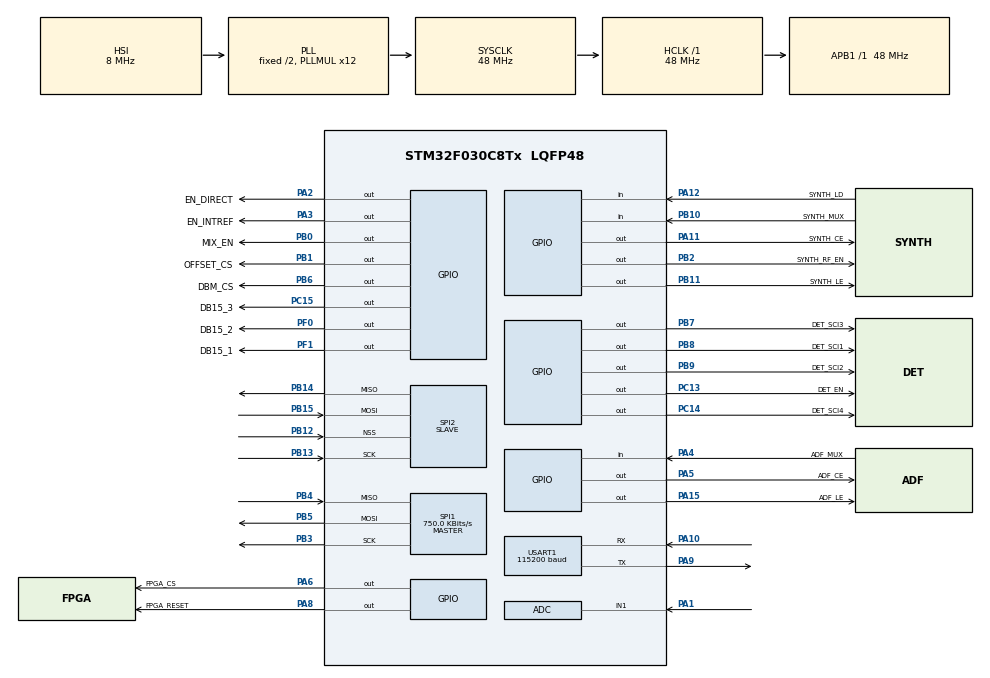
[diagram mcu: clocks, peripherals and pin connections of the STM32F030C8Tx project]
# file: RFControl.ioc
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ADC.Channel-0\#ChannelRegularConversion=ADC_CHANNEL_1
ADC.Channel-IN1=ADC_CHANNEL_1
ADC.ClockPrescaler=ADC_CLOCK_ASYNC_DIV1
ADC.ContinuousConvMode=ENABLE
ADC.DMAContinuousRequests=ENABLE
ADC.DataAlign=ADC_DATAALIGN_RIGHT
ADC.DiscontinuousConvMode=DISABLE
ADC.EOCSelection=ADC_EOC_SINGLE_CONV
ADC.EnableAnalogWatchDog=false
ADC.ExternalTrigConv=ADC_SOFTWARE_START
ADC.ExternalTrigConvEdge=ADC_EXTERNALTRIGCONVEDGE_NONE
ADC.LowPowerAutoPowerOff=DISABLE
ADC.LowPowerAutoWait=DISABLE
ADC.NbrOfConversion=1
ADC.NbrOfConversionFlag=1
ADC.Overrun=ADC_OVR_DATA_PRESERVED
ADC.Rank-0\#ChannelRegularConversion=1
ADC.Resolution=ADC_RESOLUTION_12B
ADC.SamplingTime=ADC_SAMPLETIME_239CYCLES_5
ADC.ScanConvMode=ADC_SCAN_DIRECTION_FORWARD
ADC.master=1
Dma.ADC.0.Direction=DMA_PERIPH_TO_MEMORY
Dma.ADC.0.Instance=DMA1_Channel1
Dma.ADC.0.MemDataAlignment=DMA_MDATAALIGN_HALFWORD
Dma.ADC.0.MemInc=DMA_MINC_ENABLE
Dma.ADC.0.Mode=DMA_CIRCULAR
Dma.ADC.0.PeriphDataAlignment=DMA_PDATAALIGN_HALFWORD
Dma.ADC.0.PeriphInc=DMA_PINC_DISABLE
Dma.ADC.0.Priority=DMA_PRIORITY_LOW
Dma.Request0=ADC
Dma.Request1=SPI2_RX
Dma.Request2=SPI2_TX
Dma.SPI2_RX.1.Direction=DMA_PERIPH_TO_MEMORY
Dma.SPI2_RX.1.Instance=DMA1_Channel4
Dma.SPI2_RX.1.MemDataAlignment=DMA_MDATAALIGN_BYTE
Dma.SPI2_RX.1.MemInc=DMA_MINC_ENABLE
Dma.SPI2_RX.1.Mode=DMA_NORMAL
Dma.SPI2_RX.1.PeriphDataAlignment=DMA_PDATAALIGN_BYTE
Dma.SPI2_RX.1.PeriphInc=DMA_PINC_DISABLE
Dma.SPI2_RX.1.Priority=DMA_PRIORITY_LOW
Dma.SPI2_TX.2.Direction=DMA_MEMORY_TO_PERIPH
Dma.SPI2_TX.2.Instance=DMA1_Channel5
Dma.SPI2_TX.2.MemDataAlignment=DMA_MDATAALIGN_BYTE
Dma.SPI2_TX.2.MemInc=DMA_MINC_ENABLE
Dma.SPI2_TX.2.Mode=DMA_NORMAL
Dma.SPI2_TX.2.PeriphDataAlignment=DMA_PDATAALIGN_BYTE
Dma.SPI2_TX.2.PeriphInc=DMA_PINC_DISABLE
Dma.SPI2_TX.2.Priority=DMA_PRIORITY_LOW
Mcu.Family=STM32F0
Mcu.Name=STM32F030C8Tx
Mcu.Package=LQFP48
NVIC.DMA1_Channel1_IRQn=true\:0\:0\:false\:false\:true\:false\:true
NVIC.DMA1_Channel4_5_IRQn=true\:0\:0\:false\:false\:true\:false\:true
PA1.Mode=IN1
PA1.Signal=ADC_IN1
PA10.Mode=Asynchronous
PA10.Signal=USART1_RX
PA11.GPIO_Label=SYNTH_CE
PA11.Signal=GPIO_Output
PA12.GPIO_Label=SYNTH_LD
PA12.GPIO_PuPd=GPIO_PULLUP
PA12.Signal=GPIO_Input
PA13.Mode=Serial_Wire
PA13.Signal=SYS_SWDIO
PA14.Mode=Serial_Wire
PA14.Signal=SYS_SWCLK
PA15.GPIO_Label=ADF_LE
PA15.Signal=GPIO_Output
PA2.GPIO_Label=EN_DIRECT
PA2.PinState=GPIO_PIN_SET
PA2.Signal=GPIO_Output
PA3.GPIO_Label=EN_INTREF
PA3.PinState=GPIO_PIN_SET
PA3.Signal=GPIO_Output
PA4.GPIO_Label=ADF_MUX
PA4.GPIO_PuPd=GPIO_PULLUP
PA4.Signal=GPIO_Input
PA5.GPIO_Label=ADF_CE
PA5.Signal=GPIO_Output
PA6.GPIO_Label=FPGA_CS
PA6.PinState=GPIO_PIN_SET
PA6.Signal=GPIO_Output
PA8.GPIO_Label=FPGA_RESET
PA8.Signal=GPIO_Output
PA9.Mode=Asynchronous
PA9.Signal=USART1_TX
PB0.GPIO_Label=MIX_EN
PB0.Signal=GPIO_Output
PB1.GPIO_Label=OFFSET_CS
PB1.PinState=GPIO_PIN_SET
PB1.Signal=GPIO_Output
PB10.GPIO_Label=SYNTH_MUX
PB10.Signal=GPIO_Input
PB11.GPIO_Label=SYNTH_LE
PB11.Signal=GPIO_Output
PB12.Mode=NSS_Signal_Hard_Input
PB12.Signal=SPI2_NSS
PB13.Mode=Full_Duplex_Slave
PB13.Signal=SPI2_SCK
PB14.Mode=Full_Duplex_Slave
PB14.Signal=SPI2_MISO
PB15.Mode=Full_Duplex_Slave
PB15.Signal=SPI2_MOSI
PB2.GPIO_Label=SYNTH_RF_EN
PB2.Signal=GPIO_Output
PB3.Mode=Full_Duplex_Master
PB3.Signal=SPI1_SCK
PB4.Mode=Full_Duplex_Master
PB4.Signal=SPI1_MISO
PB5.Mode=Full_Duplex_Master
PB5.Signal=SPI1_MOSI
PB6.GPIO_Label=DBM_CS
PB6.PinState=GPIO_PIN_SET
PB6.Signal=GPIO_Output
PB7.GPIO_Label=DET_SCI3
PB7.Signal=GPIO_Output
PB8.GPIO_Label=DET_SCI1
PB8.Signal=GPIO_Output
PB9.GPIO_Label=DET_SCI2
PB9.Signal=GPIO_Output
PC13.GPIO_Label=DET_EN
PC13.PinState=GPIO_PIN_SET
PC13.Signal=GPIO_Output
PC14-OSC32_IN.GPIO_Label=DET_SCI4
PC14-OSC32_IN.Signal=GPIO_Output
PC15-OSC32_OUT.GPIO_Label=DB15_3
PC15-OSC32_OUT.PinState=GPIO_PIN_SET
PC15-OSC32_OUT.Signal=GPIO_Output
PF0-OSC_IN.GPIO_Label=DB15_2
PF0-OSC_IN.PinState=GPIO_PIN_SET
PF0-OSC_IN.Signal=GPIO_Output
PF1-OSC_OUT.GPIO_Label=DB15_1
PF1-OSC_OUT.PinState=GPIO_PIN_SET
PF1-OSC_OUT.Signal=GPIO_Output
ProjectManager.HeapSize=0x200
ProjectManager.StackSize=0x400
ProjectManager.TargetToolchain=SW4STM32
RCC.AHBFreq_Value=48000000
RCC.APB1Freq_Value=48000000
RCC.APB1TimFreq_Value=48000000
RCC.FLatency=FLASH_LATENCY_1
RCC.HCLKFreq_Value=48000000
RCC.PLLMUL=RCC_PLL_MUL12
RCC.RCC_MCOSource=RCC_MCO1SOURCE_HSI
RCC.SYSCLKFreq_VALUE=48000000
RCC.SYSCLKSource=RCC_SYSCLKSOURCE_PLLCLK
SPI1.BaudRatePrescaler=SPI_BAUDRATEPRESCALER_64
SPI1.CLKPhase=SPI_PHASE_1EDGE
SPI1.CLKPolarity=SPI_POLARITY_LOW
SPI1.CRCCalculation=SPI_CRCCALCULATION_DISABLE
SPI1.CalculateBaudRate=750.0 KBits/s
SPI1.DataSize=SPI_DATASIZE_8BIT
SPI1.Direction=SPI_DIRECTION_2LINES
SPI1.FirstBit=SPI_FIRSTBIT_MSB
SPI1.Mode=SPI_MODE_MASTER
SPI1.NSS=SPI_NSS_SOFT
SPI1.NSSPMode=SPI_NSS_PULSE_ENABLE
SPI1.TIMode=SPI_TIMODE_DISABLE
SPI1.VirtualType=VM_MASTER
SPI2.CLKPhase=SPI_PHASE_1EDGE
SPI2.CLKPolarity=SPI_POLARITY_LOW
SPI2.CRCCalculation=SPI_CRCCALCULATION_DISABLE
SPI2.DataSize=SPI_DATASIZE_8BIT
SPI2.Direction=SPI_DIRECTION_2LINES
SPI2.FirstBit=SPI_FIRSTBIT_MSB
SPI2.Mode=SPI_MODE_SLAVE
SPI2.NSS=SPI_NSS_HARD_INPUT
SPI2.TIMode=SPI_TIMODE_DISABLE
SPI2.VirtualNSS=VM_NSSHARD
SPI2.VirtualType=VM_SLAVE
TIM1.AutoReloadPreload=TIM_AUTORELOAD_PRELOAD_DISABLE
TIM1.ClockDivision=TIM_CLOCKDIVISION_DIV1
TIM1.CounterMode=TIM_COUNTERMODE_UP
TIM1.Period=65535
TIM1.Prescaler=47
TIM1.RepetitionCounter=0
TIM1.TIM_MasterOutputTrigger=TIM_TRGO_RESET
TIM1.TIM_MasterSlaveMode=TIM_MASTERSLAVEMODE_DISABLE
USART1.AutoBaudRateEnableParam=UART_ADVFEATURE_AUTOBAUDRATE_DISABLE
USART1.BaudRate=115200
USART1.DMADisableonRxErrorParam=ADVFEATURE_DMA_ENABLEONRXERROR
USART1.DataInvertParam=ADVFEATURE_DATAINV_DISABLE
USART1.MSBFirstParam=ADVFEATURE_MSBFIRST_DISABLE
USART1.Mode=MODE_TX_RX
USART1.OneBitSampling=UART_ONE_BIT_SAMPLE_DISABLE
USART1.OverSampling=UART_OVERSAMPLING_16
USART1.OverrunDisableParam=ADVFEATURE_OVERRUN_ENABLE
USART1.Parity=PARITY_NONE
USART1.RxPinLevelInvertParam=ADVFEATURE_RXINV_DISABLE
USART1.StopBits=STOPBITS_1
USART1.SwapParam=ADVFEATURE_SWAP_DISABLE
USART1.TxPinLevelInvertParam=ADVFEATURE_TXINV_DISABLE
USART1.VirtualMode-Asynchronous=VM_ASYNC
USART1.WordLength=WORDLENGTH_8B
VP_TIM1_VS_ClockSourceINT.Mode=Internal
board=RFControl

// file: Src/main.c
/* USER CODE BEGIN Header */
/**
  ******************************************************************************
  * @file           : main.c
  * @brief          : Main program body
  ******************************************************************************
  * @attention
  *
  * <h2><center>&copy; Copyright (c) 2019 STMicroelectronics.
  * All rights reserved.</center></h2>
  *
  * This software component is licensed by ST under BSD 3-Clause license,
  * the "License"; You may not use this file except in compliance with the
  * License. You may obtain a copy of the License at:
  *                        opensource.org/licenses/BSD-3-Clause
  *
  ******************************************************************************
  */
/* USER CODE END Header */

#include "main.h"

/* USER CODE BEGIN Includes */
#include "../Application/app.h"
/* USER CODE END Includes */

ADC_HandleTypeDef hadc;
DMA_HandleTypeDef hdma_adc;

SPI_HandleTypeDef hspi1;
SPI_HandleTypeDef hspi2;
DMA_HandleTypeDef hdma_spi2_rx;
DMA_HandleTypeDef hdma_spi2_tx;

TIM_HandleTypeDef htim1;

UART_HandleTypeDef huart1;

void SystemClock_Config(void);
static void MX_GPIO_Init(void);
static void MX_DMA_Init(void);
static void MX_USART1_UART_Init(void);
static void MX_SPI1_Init(void);
static void MX_ADC_Init(void);
static void MX_SPI2_Init(void);
static void MX_TIM1_Init(void);

int main(void)
{

  /* MCU Configuration--------------------------------------------------------*/

  /* Reset of all peripherals, Initializes the Flash interface and the Systick. */
  HAL_Init();

  /* Configure the system clock */
  SystemClock_Config();

  /* Initialize all configured peripherals */
  MX_GPIO_Init();
  MX_DMA_Init();
  MX_USART1_UART_Init();
  MX_SPI1_Init();
  MX_ADC_Init();
  MX_SPI2_Init();
  MX_TIM1_Init();

  /* Infinite loop */
  /* USER CODE BEGIN WHILE */
  app();
  while (1)
  {
    /* USER CODE END WHILE */

  }
}

void SystemClock_Config(void)
{
  RCC_OscInitTypeDef RCC_OscInitStruct = {0};
  RCC_ClkInitTypeDef RCC_ClkInitStruct = {0};
  RCC_PeriphCLKInitTypeDef PeriphClkInit = {0};

  /** Initializes the CPU, AHB and APB busses clocks
  */
  RCC_OscInitStruct.OscillatorType = RCC_OSCILLATORTYPE_HSI|RCC_OSCILLATORTYPE_HSI14;
  RCC_OscInitStruct.HSIState = RCC_HSI_ON;
  RCC_OscInitStruct.HSI14State = RCC_HSI14_ON;
  RCC_OscInitStruct.HSICalibrationValue = RCC_HSICALIBRATION_DEFAULT;
  RCC_OscInitStruct.HSI14CalibrationValue = 16;
  RCC_OscInitStruct.PLL.PLLState = RCC_PLL_ON;
  RCC_OscInitStruct.PLL.PLLSource = RCC_PLLSOURCE_HSI;
  RCC_OscInitStruct.PLL.PLLMUL = RCC_PLL_MUL12;
  RCC_OscInitStruct.PLL.PREDIV = RCC_PREDIV_DIV1;
  if (HAL_RCC_OscConfig(&RCC_OscInitStruct) != HAL_OK)
  {
    Error_Handler();
  }
  /** Initializes the CPU, AHB and APB busses clocks
  */
  RCC_ClkInitStruct.ClockType = RCC_CLOCKTYPE_HCLK|RCC_CLOCKTYPE_SYSCLK
                              |RCC_CLOCKTYPE_PCLK1;
  RCC_ClkInitStruct.SYSCLKSource = RCC_SYSCLKSOURCE_PLLCLK;
  RCC_ClkInitStruct.AHBCLKDivider = RCC_SYSCLK_DIV1;
  RCC_ClkInitStruct.APB1CLKDivider = RCC_HCLK_DIV1;

  if (HAL_RCC_ClockConfig(&RCC_ClkInitStruct, FLASH_LATENCY_1) != HAL_OK)
  {
    Error_Handler();
  }
  PeriphClkInit.PeriphClockSelection = RCC_PERIPHCLK_USART1;
  PeriphClkInit.Usart1ClockSelection = RCC_USART1CLKSOURCE_PCLK1;
  if (HAL_RCCEx_PeriphCLKConfig(&PeriphClkInit) != HAL_OK)
  {
    Error_Handler();
  }
}

static void MX_ADC_Init(void)
{

  ADC_ChannelConfTypeDef sConfig = {0};

  /** Configure the global features of the ADC (Clock, Resolution, Data Alignment and number of conversion)
  */
  hadc.Instance = ADC1;
  hadc.Init.ClockPrescaler = ADC_CLOCK_ASYNC_DIV1;
  hadc.Init.Resolution = ADC_RESOLUTION_12B;
  hadc.Init.DataAlign = ADC_DATAALIGN_RIGHT;
  hadc.Init.ScanConvMode = ADC_SCAN_DIRECTION_FORWARD;
  hadc.Init.EOCSelection = ADC_EOC_SINGLE_CONV;
  hadc.Init.LowPowerAutoWait = DISABLE;
  hadc.Init.LowPowerAutoPowerOff = DISABLE;
  hadc.Init.ContinuousConvMode = ENABLE;
  hadc.Init.DiscontinuousConvMode = DISABLE;
  hadc.Init.ExternalTrigConv = ADC_SOFTWARE_START;
  hadc.Init.ExternalTrigConvEdge = ADC_EXTERNALTRIGCONVEDGE_NONE;
  hadc.Init.DMAContinuousRequests = ENABLE;
  hadc.Init.Overrun = ADC_OVR_DATA_PRESERVED;
  if (HAL_ADC_Init(&hadc) != HAL_OK)
  {
    Error_Handler();
  }
  /** Configure for the selected ADC regular channel to be converted.
  */
  sConfig.Channel = ADC_CHANNEL_1;
  sConfig.Rank = ADC_RANK_CHANNEL_NUMBER;
  sConfig.SamplingTime = ADC_SAMPLETIME_239CYCLES_5;
  if (HAL_ADC_ConfigChannel(&hadc, &sConfig) != HAL_OK)
  {
    Error_Handler();
  }

}

static void MX_SPI1_Init(void)
{

  /* SPI1 parameter configuration*/
  hspi1.Instance = SPI1;
  hspi1.Init.Mode = SPI_MODE_MASTER;
  hspi1.Init.Direction = SPI_DIRECTION_2LINES;
  hspi1.Init.DataSize = SPI_DATASIZE_8BIT;
  hspi1.Init.CLKPolarity = SPI_POLARITY_LOW;
  hspi1.Init.CLKPhase = SPI_PHASE_1EDGE;
  hspi1.Init.NSS = SPI_NSS_SOFT;
  hspi1.Init.BaudRatePrescaler = SPI_BAUDRATEPRESCALER_64;
  hspi1.Init.FirstBit = SPI_FIRSTBIT_MSB;
  hspi1.Init.TIMode = SPI_TIMODE_DISABLE;
  hspi1.Init.CRCCalculation = SPI_CRCCALCULATION_DISABLE;
  hspi1.Init.CRCPolynomial = 7;
  hspi1.Init.CRCLength = SPI_CRC_LENGTH_DATASIZE;
  hspi1.Init.NSSPMode = SPI_NSS_PULSE_ENABLE;
  if (HAL_SPI_Init(&hspi1) != HAL_OK)
  {
    Error_Handler();
  }

}

static void MX_SPI2_Init(void)
{

  /* SPI2 parameter configuration*/
  hspi2.Instance = SPI2;
  hspi2.Init.Mode = SPI_MODE_SLAVE;
  hspi2.Init.Direction = SPI_DIRECTION_2LINES;
  hspi2.Init.DataSize = SPI_DATASIZE_8BIT;
  hspi2.Init.CLKPolarity = SPI_POLARITY_LOW;
  hspi2.Init.CLKPhase = SPI_PHASE_1EDGE;
  hspi2.Init.NSS = SPI_NSS_HARD_INPUT;
  hspi2.Init.FirstBit = SPI_FIRSTBIT_MSB;
  hspi2.Init.TIMode = SPI_TIMODE_DISABLE;
  hspi2.Init.CRCCalculation = SPI_CRCCALCULATION_DISABLE;
  hspi2.Init.CRCPolynomial = 7;
  hspi2.Init.CRCLength = SPI_CRC_LENGTH_DATASIZE;
  hspi2.Init.NSSPMode = SPI_NSS_PULSE_DISABLE;
  if (HAL_SPI_Init(&hspi2) != HAL_OK)
  {
    Error_Handler();
  }

}

static void MX_TIM1_Init(void)
{

  TIM_ClockConfigTypeDef sClockSourceConfig = {0};
  TIM_MasterConfigTypeDef sMasterConfig = {0};

  htim1.Instance = TIM1;
  htim1.Init.Prescaler = 47;
  htim1.Init.CounterMode = TIM_COUNTERMODE_UP;
  htim1.Init.Period = 65535;
  htim1.Init.ClockDivision = TIM_CLOCKDIVISION_DIV1;
  htim1.Init.RepetitionCounter = 0;
  htim1.Init.AutoReloadPreload = TIM_AUTORELOAD_PRELOAD_DISABLE;
  if (HAL_TIM_Base_Init(&htim1) != HAL_OK)
  {
    Error_Handler();
  }
  sClockSourceConfig.ClockSource = TIM_CLOCKSOURCE_INTERNAL;
  if (HAL_TIM_ConfigClockSource(&htim1, &sClockSourceConfig) != HAL_OK)
  {
    Error_Handler();
  }
  sMasterConfig.MasterOutputTrigger = TIM_TRGO_RESET;
  sMasterConfig.MasterSlaveMode = TIM_MASTERSLAVEMODE_DISABLE;
  if (HAL_TIMEx_MasterConfigSynchronization(&htim1, &sMasterConfig) != HAL_OK)
  {
    Error_Handler();
  }

}

static void MX_USART1_UART_Init(void)
{

  huart1.Instance = USART1;
  huart1.Init.BaudRate = 115200;
  huart1.Init.WordLength = UART_WORDLENGTH_8B;
  huart1.Init.StopBits = UART_STOPBITS_1;
  huart1.Init.Parity = UART_PARITY_NONE;
  huart1.Init.Mode = UART_MODE_TX_RX;
  huart1.Init.HwFlowCtl = UART_HWCONTROL_NONE;
  huart1.Init.OverSampling = UART_OVERSAMPLING_16;
  huart1.Init.OneBitSampling = UART_ONE_BIT_SAMPLE_DISABLE;
  huart1.AdvancedInit.AdvFeatureInit = UART_ADVFEATURE_NO_INIT;
  if (HAL_UART_Init(&huart1) != HAL_OK)
  {
    Error_Handler();
  }

}

static void MX_DMA_Init(void)
{
  /* DMA controller clock enable */
  __HAL_RCC_DMA1_CLK_ENABLE();

  /* DMA interrupt init */
  /* DMA1_Channel1_IRQn interrupt configuration */
  HAL_NVIC_SetPriority(DMA1_Channel1_IRQn, 0, 0);
  HAL_NVIC_EnableIRQ(DMA1_Channel1_IRQn);
  /* DMA1_Channel4_5_IRQn interrupt configuration */
  HAL_NVIC_SetPriority(DMA1_Channel4_5_IRQn, 0, 0);
  HAL_NVIC_EnableIRQ(DMA1_Channel4_5_IRQn);

}

static void MX_GPIO_Init(void)
{
  GPIO_InitTypeDef GPIO_InitStruct = {0};

  /* GPIO Ports Clock Enable */
  __HAL_RCC_GPIOC_CLK_ENABLE();
  __HAL_RCC_GPIOF_CLK_ENABLE();
  __HAL_RCC_GPIOA_CLK_ENABLE();
  __HAL_RCC_GPIOB_CLK_ENABLE();

  /*Configure GPIO pin Output Level */
  HAL_GPIO_WritePin(GPIOC, DET_EN_Pin|DB15_3_Pin, GPIO_PIN_SET);

  /*Configure GPIO pin Output Level */
  HAL_GPIO_WritePin(DET_SCI4_GPIO_Port, DET_SCI4_Pin, GPIO_PIN_RESET);

  /*Configure GPIO pin Output Level */
  HAL_GPIO_WritePin(GPIOF, DB15_2_Pin|DB15_1_Pin, GPIO_PIN_SET);

  /*Configure GPIO pin Output Level */
  HAL_GPIO_WritePin(GPIOA, EN_DIRECT_Pin|EN_INTREF_Pin|FPGA_CS_Pin, GPIO_PIN_SET);

  /*Configure GPIO pin Output Level */
  HAL_GPIO_WritePin(GPIOA, ADF_CE_Pin|FPGA_RESET_Pin|SYNTH_CE_Pin|ADF_LE_Pin, GPIO_PIN_RESET);

  /*Configure GPIO pin Output Level */
  HAL_GPIO_WritePin(GPIOB, MIX_EN_Pin|SYNTH_RF_EN_Pin|SYNTH_LE_Pin|DET_SCI3_Pin
                          |DET_SCI1_Pin|DET_SCI2_Pin, GPIO_PIN_RESET);

  /*Configure GPIO pin Output Level */
  HAL_GPIO_WritePin(GPIOB, OFFSET_CS_Pin|DBM_CS_Pin, GPIO_PIN_SET);

  /*Configure GPIO pins : DET_EN_Pin DET_SCI4_Pin DB15_3_Pin */
  GPIO_InitStruct.Pin = DET_EN_Pin|DET_SCI4_Pin|DB15_3_Pin;
  GPIO_InitStruct.Mode = GPIO_MODE_OUTPUT_PP;
  GPIO_InitStruct.Pull = GPIO_NOPULL;
  GPIO_InitStruct.Speed = GPIO_SPEED_FREQ_LOW;
  HAL_GPIO_Init(GPIOC, &GPIO_InitStruct);

  /*Configure GPIO pins : DB15_2_Pin DB15_1_Pin */
  GPIO_InitStruct.Pin = DB15_2_Pin|DB15_1_Pin;
  GPIO_InitStruct.Mode = GPIO_MODE_OUTPUT_PP;
  GPIO_InitStruct.Pull = GPIO_NOPULL;
  GPIO_InitStruct.Speed = GPIO_SPEED_FREQ_LOW;
  HAL_GPIO_Init(GPIOF, &GPIO_InitStruct);

  /*Configure GPIO pins : EN_DIRECT_Pin EN_INTREF_Pin ADF_CE_Pin FPGA_CS_Pin
                           FPGA_RESET_Pin SYNTH_CE_Pin ADF_LE_Pin */
  GPIO_InitStruct.Pin = EN_DIRECT_Pin|EN_INTREF_Pin|ADF_CE_Pin|FPGA_CS_Pin
                          |FPGA_RESET_Pin|SYNTH_CE_Pin|ADF_LE_Pin;
  GPIO_InitStruct.Mode = GPIO_MODE_OUTPUT_PP;
  GPIO_InitStruct.Pull = GPIO_NOPULL;
  GPIO_InitStruct.Speed = GPIO_SPEED_FREQ_LOW;
  HAL_GPIO_Init(GPIOA, &GPIO_InitStruct);

  /*Configure GPIO pins : ADF_MUX_Pin SYNTH_LD_Pin */
  GPIO_InitStruct.Pin = ADF_MUX_Pin|SYNTH_LD_Pin;
  GPIO_InitStruct.Mode = GPIO_MODE_INPUT;
  GPIO_InitStruct.Pull = GPIO_PULLUP;
  HAL_GPIO_Init(GPIOA, &GPIO_InitStruct);

  /*Configure GPIO pins : MIX_EN_Pin OFFSET_CS_Pin SYNTH_RF_EN_Pin SYNTH_LE_Pin
                           DBM_CS_Pin DET_SCI3_Pin DET_SCI1_Pin DET_SCI2_Pin */
  GPIO_InitStruct.Pin = MIX_EN_Pin|OFFSET_CS_Pin|SYNTH_RF_EN_Pin|SYNTH_LE_Pin
                          |DBM_CS_Pin|DET_SCI3_Pin|DET_SCI1_Pin|DET_SCI2_Pin;
  GPIO_InitStruct.Mode = GPIO_MODE_OUTPUT_PP;
  GPIO_InitStruct.Pull = GPIO_NOPULL;
  GPIO_InitStruct.Speed = GPIO_SPEED_FREQ_LOW;
  HAL_GPIO_Init(GPIOB, &GPIO_InitStruct);

  /*Configure GPIO pin : SYNTH_MUX_Pin */
  GPIO_InitStruct.Pin = SYNTH_MUX_Pin;
  GPIO_InitStruct.Mode = GPIO_MODE_INPUT;
  GPIO_InitStruct.Pull = GPIO_NOPULL;
  HAL_GPIO_Init(SYNTH_MUX_GPIO_Port, &GPIO_InitStruct);

}

void Error_Handler(void)
{
}

/************************ (C) COPYRIGHT STMicroelectronics *****END OF FILE****/
